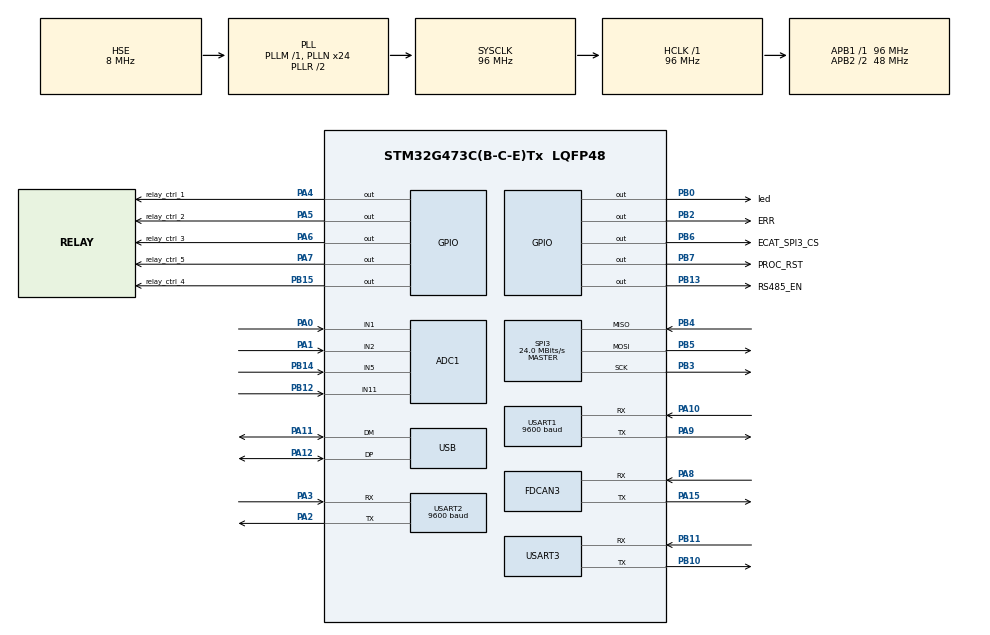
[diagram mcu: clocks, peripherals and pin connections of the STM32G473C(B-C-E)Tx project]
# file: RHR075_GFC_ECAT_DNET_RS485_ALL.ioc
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ADC1.Channel-0\#ChannelRegularConversion=ADC_CHANNEL_1
ADC1.Channel-1\#ChannelRegularConversion=ADC_CHANNEL_2
ADC1.Channel-2\#ChannelRegularConversion=ADC_CHANNEL_5
ADC1.Channel-3\#ChannelRegularConversion=ADC_CHANNEL_11
ADC1.Channel-4\#ChannelRegularConversion=ADC_CHANNEL_VREFINT
ADC1.ClockPrescaler=ADC_CLOCK_SYNC_PCLK_DIV2
ADC1.ContinuousConvMode=ENABLE
ADC1.DMAContinuousRequests=DISABLE
ADC1.NbrOfConversion=5
ADC1.NbrOfConversionFlag=1
ADC1.OffsetNumber-0\#ChannelRegularConversion=ADC_OFFSET_NONE
ADC1.OffsetNumber-1\#ChannelRegularConversion=ADC_OFFSET_NONE
ADC1.OffsetNumber-2\#ChannelRegularConversion=ADC_OFFSET_NONE
ADC1.OffsetNumber-3\#ChannelRegularConversion=ADC_OFFSET_NONE
ADC1.OffsetNumber-4\#ChannelRegularConversion=ADC_OFFSET_NONE
ADC1.Rank-0\#ChannelRegularConversion=1
ADC1.Rank-1\#ChannelRegularConversion=2
ADC1.Rank-2\#ChannelRegularConversion=3
ADC1.Rank-3\#ChannelRegularConversion=4
ADC1.Rank-4\#ChannelRegularConversion=5
ADC1.SamplingTime-0\#ChannelRegularConversion=ADC_SAMPLETIME_92CYCLES_5
ADC1.SamplingTime-1\#ChannelRegularConversion=ADC_SAMPLETIME_92CYCLES_5
ADC1.SamplingTime-2\#ChannelRegularConversion=ADC_SAMPLETIME_92CYCLES_5
ADC1.SamplingTime-3\#ChannelRegularConversion=ADC_SAMPLETIME_92CYCLES_5
ADC1.SamplingTime-4\#ChannelRegularConversion=ADC_SAMPLETIME_92CYCLES_5
ADC1.master=1
Dma.ADC1.0.Direction=DMA_PERIPH_TO_MEMORY
Dma.ADC1.0.EventEnable=DISABLE
Dma.ADC1.0.Instance=DMA1_Channel1
Dma.ADC1.0.MemDataAlignment=DMA_MDATAALIGN_HALFWORD
Dma.ADC1.0.MemInc=DMA_MINC_ENABLE
Dma.ADC1.0.Mode=DMA_CIRCULAR
Dma.ADC1.0.PeriphDataAlignment=DMA_PDATAALIGN_HALFWORD
Dma.ADC1.0.PeriphInc=DMA_PINC_DISABLE
Dma.ADC1.0.Polarity=HAL_DMAMUX_REQ_GEN_RISING
Dma.ADC1.0.Priority=DMA_PRIORITY_LOW
Dma.ADC1.0.RequestNumber=1
Dma.ADC1.0.SignalID=NONE
Dma.ADC1.0.SyncEnable=DISABLE
Dma.ADC1.0.SyncPolarity=HAL_DMAMUX_SYNC_NO_EVENT
Dma.ADC1.0.SyncRequestNumber=1
Dma.ADC1.0.SyncSignalID=NONE
Dma.Request0=ADC1
Dma.Request1=USART2_RX
Dma.Request2=USART3_RX
Dma.USART2_RX.1.Direction=DMA_PERIPH_TO_MEMORY
Dma.USART2_RX.1.EventEnable=DISABLE
Dma.USART2_RX.1.Instance=DMA1_Channel3
Dma.USART2_RX.1.MemDataAlignment=DMA_MDATAALIGN_BYTE
Dma.USART2_RX.1.MemInc=DMA_MINC_ENABLE
Dma.USART2_RX.1.Mode=DMA_NORMAL
Dma.USART2_RX.1.PeriphDataAlignment=DMA_PDATAALIGN_BYTE
Dma.USART2_RX.1.PeriphInc=DMA_PINC_DISABLE
Dma.USART2_RX.1.Polarity=HAL_DMAMUX_REQ_GEN_RISING
Dma.USART2_RX.1.Priority=DMA_PRIORITY_LOW
Dma.USART2_RX.1.RequestNumber=1
Dma.USART2_RX.1.SignalID=NONE
Dma.USART2_RX.1.SyncEnable=DISABLE
Dma.USART2_RX.1.SyncPolarity=HAL_DMAMUX_SYNC_NO_EVENT
Dma.USART2_RX.1.SyncRequestNumber=1
Dma.USART2_RX.1.SyncSignalID=NONE
Dma.USART3_RX.2.Direction=DMA_PERIPH_TO_MEMORY
Dma.USART3_RX.2.EventEnable=DISABLE
Dma.USART3_RX.2.Instance=DMA1_Channel4
Dma.USART3_RX.2.MemDataAlignment=DMA_MDATAALIGN_BYTE
Dma.USART3_RX.2.MemInc=DMA_MINC_ENABLE
Dma.USART3_RX.2.Mode=DMA_NORMAL
Dma.USART3_RX.2.PeriphDataAlignment=DMA_PDATAALIGN_BYTE
Dma.USART3_RX.2.PeriphInc=DMA_PINC_DISABLE
Dma.USART3_RX.2.Polarity=HAL_DMAMUX_REQ_GEN_RISING
Dma.USART3_RX.2.Priority=DMA_PRIORITY_LOW
Dma.USART3_RX.2.RequestNumber=1
Dma.USART3_RX.2.SignalID=NONE
Dma.USART3_RX.2.SyncEnable=DISABLE
Dma.USART3_RX.2.SyncPolarity=HAL_DMAMUX_SYNC_NO_EVENT
Dma.USART3_RX.2.SyncRequestNumber=1
Dma.USART3_RX.2.SyncSignalID=NONE
FDCAN3.CalculateBaudRateNominal=1200000
FDCAN3.CalculateTimeBitNominal=833
FDCAN3.CalculateTimeQuantumNominal=166.66666666666666
Mcu.Family=STM32G4
Mcu.Name=STM32G473C(B-C-E)Tx
Mcu.Package=LQFP48
NVIC.ADC1_2_IRQn=true\:0\:0\:false\:false\:true\:true\:true\:true
NVIC.DMA1_Channel1_IRQn=true\:0\:0\:false\:false\:true\:false\:true\:true
NVIC.DMA1_Channel3_IRQn=true\:0\:0\:false\:false\:true\:false\:true\:true
NVIC.DMA1_Channel4_IRQn=true\:0\:0\:false\:false\:true\:false\:true\:true
NVIC.PriorityGroup=NVIC_PRIORITYGROUP_4
NVIC.USART1_IRQn=true\:0\:0\:false\:false\:true\:true\:true\:true
NVIC.USART2_IRQn=true\:0\:0\:false\:false\:true\:true\:true\:true
NVIC.USART3_IRQn=true\:0\:0\:false\:false\:true\:true\:true\:true
PA0.Mode=IN1-Single-Ended
PA0.Signal=ADC1_IN1
PA1.Mode=IN2-Single-Ended
PA1.Signal=ADC1_IN2
PA10.Mode=Asynchronous
PA10.Signal=USART1_RX
PA11.Mode=Device
PA11.Signal=USB_DM
PA12.Mode=Device
PA12.Signal=USB_DP
PA13.Mode=Serial_Wire
PA13.Signal=SYS_JTMS-SWDIO
PA14.Mode=Serial_Wire
PA14.Signal=SYS_JTCK-SWCLK
PA15.Mode=FDCAN_Activate
PA15.Signal=FDCAN3_TX
PA2.Mode=Asynchronous
PA2.Signal=USART2_TX
PA3.Mode=Asynchronous
PA3.Signal=USART2_RX
PA4.GPIO_Label=relay_ctrl_1
PA4.GPIO_PuPd=GPIO_PULLUP
PA4.PinState=GPIO_PIN_SET
PA4.Signal=GPIO_Output
PA5.GPIO_Label=relay_ctrl_2
PA5.GPIO_PuPd=GPIO_PULLUP
PA5.PinState=GPIO_PIN_SET
PA5.Signal=GPIO_Output
PA6.GPIO_Label=relay_ctrl_3
PA6.GPIO_PuPd=GPIO_PULLUP
PA6.PinState=GPIO_PIN_SET
PA6.Signal=GPIO_Output
PA7.GPIO_Label=relay_ctrl_5
PA7.GPIO_PuPd=GPIO_PULLUP
PA7.PinState=GPIO_PIN_SET
PA7.Signal=GPIO_Output
PA8.Mode=FDCAN_Activate
PA8.Signal=FDCAN3_RX
PA9.Mode=Asynchronous
PA9.Signal=USART1_TX
PB0.GPIO_Label=led
PB0.Signal=GPIO_Output
PB10.Mode=Asynchronous
PB10.Signal=USART3_TX
PB11.Mode=Asynchronous
PB11.Signal=USART3_RX
PB12.Mode=IN11-Single-Ended
PB12.Signal=ADC1_IN11
PB13.GPIO_Label=RS485_EN
PB13.GPIO_PuPd=GPIO_PULLDOWN
PB13.Signal=GPIO_Output
PB14.Mode=IN5-Single-Ended
PB14.Signal=ADC1_IN5
PB15.GPIO_Label=relay_ctrl_4
PB15.GPIO_PuPd=GPIO_PULLUP
PB15.PinState=GPIO_PIN_SET
PB15.Signal=GPIO_Output
PB2.GPIO_Label=ERR
PB2.Signal=GPIO_Output
PB3.Mode=Full_Duplex_Master
PB3.Signal=SPI3_SCK
PB4.Mode=Full_Duplex_Master
PB4.Signal=SPI3_MISO
PB5.Mode=Full_Duplex_Master
PB5.Signal=SPI3_MOSI
PB6.GPIO_Label=ECAT_SPI3_CS
PB6.GPIO_PuPd=GPIO_PULLUP
PB6.PinState=GPIO_PIN_SET
PB6.Signal=GPIO_Output
PB7.GPIO_Label=PROC_RST
PB7.GPIO_PuPd=GPIO_PULLUP
PB7.PinState=GPIO_PIN_SET
PB7.Signal=GPIO_Output
PF0-OSC_IN.Mode=HSE-External-Oscillator
PF0-OSC_IN.Signal=RCC_OSC_IN
PF1-OSC_OUT.Mode=HSE-External-Oscillator
PF1-OSC_OUT.Signal=RCC_OSC_OUT
ProjectManager.HeapSize=0x200
ProjectManager.StackSize=0x400
ProjectManager.TargetToolchain=MDK-ARM V5.32
RCC.ADC12Freq_Value=96000000
RCC.ADC345Freq_Value=96000000
RCC.AHBFreq_Value=96000000
RCC.APB1Freq_Value=96000000
RCC.APB1TimFreq_Value=96000000
RCC.APB2CLKDivider=RCC_HCLK_DIV2
RCC.APB2Freq_Value=48000000
RCC.APB2TimFreq_Value=96000000
RCC.CortexFreq_Value=96000000
RCC.EXTERNAL_CLOCK_VALUE=12288000
RCC.HCLKFreq_Value=96000000
RCC.HSE_VALUE=8000000
RCC.HSI48_VALUE=48000000
RCC.HSI_VALUE=16000000
RCC.LSE_VALUE=32768
RCC.PLLN=24
RCC.PLLQ=RCC_PLLQ_DIV4
RCC.PLLSourceVirtual=RCC_PLLSOURCE_HSE
RCC.SYSCLKFreq_VALUE=96000000
RCC.SYSCLKSource=RCC_SYSCLKSOURCE_PLLCLK
RCC.USBFreq_Value=48000000
RCC.VCOOutputFreq_Value=192000000
SPI3.BaudRatePrescaler=SPI_BAUDRATEPRESCALER_4
SPI3.CalculateBaudRate=24.0 MBits/s
SPI3.Direction=SPI_DIRECTION_2LINES
SPI3.Mode=SPI_MODE_MASTER
SPI3.VirtualType=VM_MASTER
USART1.BaudRate=9600
USART1.VirtualMode-Asynchronous=VM_ASYNC
USART2.BaudRate=9600
USART2.VirtualMode-Asynchronous=VM_ASYNC
USART3.VirtualMode-Asynchronous=VM_ASYNC
VP_ADC1_Vref_Input.Mode=IN-Vrefint
VP_SYS_VS_DBSignals.Mode=DisableDeadBatterySignals
board=custom

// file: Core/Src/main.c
/* USER CODE BEGIN Header */
/**
  ******************************************************************************
  * @file           : main.c
  * @brief          : Main program body
  ******************************************************************************
  * @attention
  *
  * Copyright (c) 2024 STMicroelectronics.
  * All rights reserved.
  *
  * This software is licensed under terms that can be found in the LICENSE file
  * in the root directory of this software component.
  * If no LICENSE file comes with this software, it is provided AS-IS.
  *
  ******************************************************************************
  */
/* USER CODE END Header */
#include "main.h"

/* USER CODE BEGIN Includes */
#include "app.h"
/* USER CODE END Includes */

ADC_HandleTypeDef hadc1;
DMA_HandleTypeDef hdma_adc1;

FDCAN_HandleTypeDef hfdcan3;

SPI_HandleTypeDef hspi3;

UART_HandleTypeDef huart1;
UART_HandleTypeDef huart2;
UART_HandleTypeDef huart3;
DMA_HandleTypeDef hdma_usart2_rx;
DMA_HandleTypeDef hdma_usart3_rx;

PCD_HandleTypeDef hpcd_USB_FS;

void SystemClock_Config(void);
static void MX_GPIO_Init(void);
static void MX_DMA_Init(void);
static void MX_ADC1_Init(void);
static void MX_FDCAN3_Init(void);
static void MX_SPI3_Init(void);
static void MX_USART1_UART_Init(void);
static void MX_USART2_UART_Init(void);
static void MX_USART3_UART_Init(void);
static void MX_USB_PCD_Init(void);

int main(void)
{

  /* MCU Configuration--------------------------------------------------------*/

  /* Reset of all peripherals, Initializes the Flash interface and the Systick. */
  HAL_Init();

  /* Configure the system clock */
  SystemClock_Config();

  /* Initialize all configured peripherals */
  MX_GPIO_Init();
  MX_DMA_Init();
  MX_ADC1_Init();
  MX_FDCAN3_Init();
  MX_SPI3_Init();
  MX_USART1_UART_Init();
  MX_USART2_UART_Init();
  MX_USART3_UART_Init();
  MX_USB_PCD_Init();
  /* USER CODE BEGIN 2 */
   app_init();
  #if DEBUG_LOG2_ENABLE
	 printf("init ok\r\n");
  #endif
  /* USER CODE END 2 */

  /* Infinite loop */
  /* USER CODE BEGIN WHILE */
  while (1)
  {
		  app_proc();

    /* USER CODE END WHILE */

  }
}

void SystemClock_Config(void)
{
  RCC_OscInitTypeDef RCC_OscInitStruct = {0};
  RCC_ClkInitTypeDef RCC_ClkInitStruct = {0};

  /** Configure the main internal regulator output voltage
  */
  HAL_PWREx_ControlVoltageScaling(PWR_REGULATOR_VOLTAGE_SCALE1);

  /** Initializes the RCC Oscillators according to the specified parameters
  * in the RCC_OscInitTypeDef structure.
  */
  RCC_OscInitStruct.OscillatorType = RCC_OSCILLATORTYPE_HSE;
  RCC_OscInitStruct.HSEState = RCC_HSE_ON;
  RCC_OscInitStruct.PLL.PLLState = RCC_PLL_ON;
  RCC_OscInitStruct.PLL.PLLSource = RCC_PLLSOURCE_HSE;
  RCC_OscInitStruct.PLL.PLLM = RCC_PLLM_DIV1;
  RCC_OscInitStruct.PLL.PLLN = 24;
  RCC_OscInitStruct.PLL.PLLP = RCC_PLLP_DIV2;
  RCC_OscInitStruct.PLL.PLLQ = RCC_PLLQ_DIV4;
  RCC_OscInitStruct.PLL.PLLR = RCC_PLLR_DIV2;
  if (HAL_RCC_OscConfig(&RCC_OscInitStruct) != HAL_OK)
  {
    Error_Handler();
  }

  /** Initializes the CPU, AHB and APB buses clocks
  */
  RCC_ClkInitStruct.ClockType = RCC_CLOCKTYPE_HCLK|RCC_CLOCKTYPE_SYSCLK
                              |RCC_CLOCKTYPE_PCLK1|RCC_CLOCKTYPE_PCLK2;
  RCC_ClkInitStruct.SYSCLKSource = RCC_SYSCLKSOURCE_PLLCLK;
  RCC_ClkInitStruct.AHBCLKDivider = RCC_SYSCLK_DIV1;
  RCC_ClkInitStruct.APB1CLKDivider = RCC_HCLK_DIV1;
  RCC_ClkInitStruct.APB2CLKDivider = RCC_HCLK_DIV2;

  if (HAL_RCC_ClockConfig(&RCC_ClkInitStruct, FLASH_LATENCY_3) != HAL_OK)
  {
    Error_Handler();
  }
}

static void MX_ADC1_Init(void)
{

  ADC_MultiModeTypeDef multimode = {0};
  ADC_ChannelConfTypeDef sConfig = {0};

  /** Common config
  */
  hadc1.Instance = ADC1;
  hadc1.Init.ClockPrescaler = ADC_CLOCK_SYNC_PCLK_DIV2;
  hadc1.Init.Resolution = ADC_RESOLUTION_12B;
  hadc1.Init.DataAlign = ADC_DATAALIGN_RIGHT;
  hadc1.Init.GainCompensation = 0;
  hadc1.Init.ScanConvMode = ADC_SCAN_ENABLE;
  hadc1.Init.EOCSelection = ADC_EOC_SINGLE_CONV;
  hadc1.Init.LowPowerAutoWait = DISABLE;
  hadc1.Init.ContinuousConvMode = ENABLE;
  hadc1.Init.NbrOfConversion = 5;
  hadc1.Init.DiscontinuousConvMode = DISABLE;
  hadc1.Init.ExternalTrigConv = ADC_SOFTWARE_START;
  hadc1.Init.ExternalTrigConvEdge = ADC_EXTERNALTRIGCONVEDGE_NONE;
  hadc1.Init.DMAContinuousRequests = DISABLE;
  hadc1.Init.Overrun = ADC_OVR_DATA_PRESERVED;
  hadc1.Init.OversamplingMode = DISABLE;
  if (HAL_ADC_Init(&hadc1) != HAL_OK)
  {
    Error_Handler();
  }

  /** Configure the ADC multi-mode
  */
  multimode.Mode = ADC_MODE_INDEPENDENT;
  if (HAL_ADCEx_MultiModeConfigChannel(&hadc1, &multimode) != HAL_OK)
  {
    Error_Handler();
  }

  /** Configure Regular Channel
  */
  sConfig.Channel = ADC_CHANNEL_1;
  sConfig.Rank = ADC_REGULAR_RANK_1;
  sConfig.SamplingTime = ADC_SAMPLETIME_24CYCLES_5;
  sConfig.SingleDiff = ADC_SINGLE_ENDED;
  sConfig.OffsetNumber = ADC_OFFSET_NONE;
  sConfig.Offset = 0;
  if (HAL_ADC_ConfigChannel(&hadc1, &sConfig) != HAL_OK)
  {
    Error_Handler();
  }

  /** Configure Regular Channel
  */
  sConfig.Channel = ADC_CHANNEL_2;
  sConfig.Rank = ADC_REGULAR_RANK_2;
  if (HAL_ADC_ConfigChannel(&hadc1, &sConfig) != HAL_OK)
  {
    Error_Handler();
  }

  /** Configure Regular Channel
  */
  sConfig.Channel = ADC_CHANNEL_5;
  sConfig.Rank = ADC_REGULAR_RANK_3;
  if (HAL_ADC_ConfigChannel(&hadc1, &sConfig) != HAL_OK)
  {
    Error_Handler();
  }

  /** Configure Regular Channel
  */
  sConfig.Channel = ADC_CHANNEL_11;
  sConfig.Rank = ADC_REGULAR_RANK_4;
  if (HAL_ADC_ConfigChannel(&hadc1, &sConfig) != HAL_OK)
  {
    Error_Handler();
  }

  /** Configure Regular Channel
  */
  sConfig.Channel = ADC_CHANNEL_VREFINT;
  sConfig.Rank = ADC_REGULAR_RANK_5;
  if (HAL_ADC_ConfigChannel(&hadc1, &sConfig) != HAL_OK)
  {
    Error_Handler();
  }

}

static void MX_FDCAN3_Init(void)
{

  hfdcan3.Instance = FDCAN3;
  hfdcan3.Init.ClockDivider = FDCAN_CLOCK_DIV1;
  hfdcan3.Init.FrameFormat = FDCAN_FRAME_CLASSIC;
  hfdcan3.Init.Mode = FDCAN_MODE_NORMAL;
  hfdcan3.Init.AutoRetransmission = DISABLE;
  hfdcan3.Init.TransmitPause = DISABLE;
  hfdcan3.Init.ProtocolException = DISABLE;
  hfdcan3.Init.NominalPrescaler = 16;
  hfdcan3.Init.NominalSyncJumpWidth = 1;
  hfdcan3.Init.NominalTimeSeg1 = 2;
  hfdcan3.Init.NominalTimeSeg2 = 2;
  hfdcan3.Init.DataPrescaler = 1;
  hfdcan3.Init.DataSyncJumpWidth = 1;
  hfdcan3.Init.DataTimeSeg1 = 1;
  hfdcan3.Init.DataTimeSeg2 = 1;
  hfdcan3.Init.StdFiltersNbr = 0;
  hfdcan3.Init.ExtFiltersNbr = 0;
  hfdcan3.Init.TxFifoQueueMode = FDCAN_TX_FIFO_OPERATION;
  if (HAL_FDCAN_Init(&hfdcan3) != HAL_OK)
  {
    Error_Handler();
  }

}

static void MX_SPI3_Init(void)
{

  /* SPI3 parameter configuration*/
  hspi3.Instance = SPI3;
  hspi3.Init.Mode = SPI_MODE_MASTER;
  hspi3.Init.Direction = SPI_DIRECTION_2LINES;
  hspi3.Init.DataSize = SPI_DATASIZE_4BIT;
  hspi3.Init.CLKPolarity = SPI_POLARITY_LOW;
  hspi3.Init.CLKPhase = SPI_PHASE_1EDGE;
  hspi3.Init.NSS = SPI_NSS_SOFT;
  hspi3.Init.BaudRatePrescaler = SPI_BAUDRATEPRESCALER_4;
  hspi3.Init.FirstBit = SPI_FIRSTBIT_MSB;
  hspi3.Init.TIMode = SPI_TIMODE_DISABLE;
  hspi3.Init.CRCCalculation = SPI_CRCCALCULATION_DISABLE;
  hspi3.Init.CRCPolynomial = 7;
  hspi3.Init.CRCLength = SPI_CRC_LENGTH_DATASIZE;
  hspi3.Init.NSSPMode = SPI_NSS_PULSE_ENABLE;
  if (HAL_SPI_Init(&hspi3) != HAL_OK)
  {
    Error_Handler();
  }

}

static void MX_USART1_UART_Init(void)
{

  huart1.Instance = USART1;
  huart1.Init.BaudRate = 9600;
  huart1.Init.WordLength = UART_WORDLENGTH_8B;
  huart1.Init.StopBits = UART_STOPBITS_1;
  huart1.Init.Parity = UART_PARITY_NONE;
  huart1.Init.Mode = UART_MODE_TX_RX;
  huart1.Init.HwFlowCtl = UART_HWCONTROL_NONE;
  huart1.Init.OverSampling = UART_OVERSAMPLING_16;
  huart1.Init.OneBitSampling = UART_ONE_BIT_SAMPLE_DISABLE;
  huart1.Init.ClockPrescaler = UART_PRESCALER_DIV1;
  huart1.AdvancedInit.AdvFeatureInit = UART_ADVFEATURE_NO_INIT;
  if (HAL_UART_Init(&huart1) != HAL_OK)
  {
    Error_Handler();
  }
  if (HAL_UARTEx_SetTxFifoThreshold(&huart1, UART_TXFIFO_THRESHOLD_1_8) != HAL_OK)
  {
    Error_Handler();
  }
  if (HAL_UARTEx_SetRxFifoThreshold(&huart1, UART_RXFIFO_THRESHOLD_1_8) != HAL_OK)
  {
    Error_Handler();
  }
  if (HAL_UARTEx_DisableFifoMode(&huart1) != HAL_OK)
  {
    Error_Handler();
  }

}

static void MX_USART2_UART_Init(void)
{

  huart2.Instance = USART2;
  huart2.Init.BaudRate = 9600;
  huart2.Init.WordLength = UART_WORDLENGTH_8B;
  huart2.Init.StopBits = UART_STOPBITS_1;
  huart2.Init.Parity = UART_PARITY_NONE;
  huart2.Init.Mode = UART_MODE_TX_RX;
  huart2.Init.HwFlowCtl = UART_HWCONTROL_NONE;
  huart2.Init.OverSampling = UART_OVERSAMPLING_16;
  huart2.Init.OneBitSampling = UART_ONE_BIT_SAMPLE_DISABLE;
  huart2.Init.ClockPrescaler = UART_PRESCALER_DIV1;
  huart2.AdvancedInit.AdvFeatureInit = UART_ADVFEATURE_NO_INIT;
  if (HAL_UART_Init(&huart2) != HAL_OK)
  {
    Error_Handler();
  }
  if (HAL_UARTEx_SetTxFifoThreshold(&huart2, UART_TXFIFO_THRESHOLD_1_8) != HAL_OK)
  {
    Error_Handler();
  }
  if (HAL_UARTEx_SetRxFifoThreshold(&huart2, UART_RXFIFO_THRESHOLD_1_8) != HAL_OK)
  {
    Error_Handler();
  }
  if (HAL_UARTEx_DisableFifoMode(&huart2) != HAL_OK)
  {
    Error_Handler();
  }

}

static void MX_USART3_UART_Init(void)
{

  huart3.Instance = USART3;
  huart3.Init.BaudRate = 115200;
  huart3.Init.WordLength = UART_WORDLENGTH_8B;
  huart3.Init.StopBits = UART_STOPBITS_1;
  huart3.Init.Parity = UART_PARITY_NONE;
  huart3.Init.Mode = UART_MODE_TX_RX;
  huart3.Init.HwFlowCtl = UART_HWCONTROL_NONE;
  huart3.Init.OverSampling = UART_OVERSAMPLING_16;
  huart3.Init.OneBitSampling = UART_ONE_BIT_SAMPLE_DISABLE;
  huart3.Init.ClockPrescaler = UART_PRESCALER_DIV1;
  huart3.AdvancedInit.AdvFeatureInit = UART_ADVFEATURE_NO_INIT;
  if (HAL_UART_Init(&huart3) != HAL_OK)
  {
    Error_Handler();
  }
  if (HAL_UARTEx_SetTxFifoThreshold(&huart3, UART_TXFIFO_THRESHOLD_1_8) != HAL_OK)
  {
    Error_Handler();
  }
  if (HAL_UARTEx_SetRxFifoThreshold(&huart3, UART_RXFIFO_THRESHOLD_1_8) != HAL_OK)
  {
    Error_Handler();
  }
  if (HAL_UARTEx_DisableFifoMode(&huart3) != HAL_OK)
  {
    Error_Handler();
  }

}

static void MX_USB_PCD_Init(void)
{

  hpcd_USB_FS.Instance = USB;
  hpcd_USB_FS.Init.dev_endpoints = 8;
  hpcd_USB_FS.Init.speed = PCD_SPEED_FULL;
  hpcd_USB_FS.Init.phy_itface = PCD_PHY_EMBEDDED;
  hpcd_USB_FS.Init.Sof_enable = DISABLE;
  hpcd_USB_FS.Init.low_power_enable = DISABLE;
  hpcd_USB_FS.Init.lpm_enable = DISABLE;
  hpcd_USB_FS.Init.battery_charging_enable = DISABLE;
  if (HAL_PCD_Init(&hpcd_USB_FS) != HAL_OK)
  {
    Error_Handler();
  }

}

static void MX_DMA_Init(void)
{

  /* DMA controller clock enable */
  __HAL_RCC_DMAMUX1_CLK_ENABLE();
  __HAL_RCC_DMA1_CLK_ENABLE();

  /* DMA interrupt init */
  /* DMA1_Channel1_IRQn interrupt configuration */
  HAL_NVIC_SetPriority(DMA1_Channel1_IRQn, 0, 0);
  HAL_NVIC_EnableIRQ(DMA1_Channel1_IRQn);
  /* DMA1_Channel3_IRQn interrupt configuration */
  HAL_NVIC_SetPriority(DMA1_Channel3_IRQn, 0, 0);
  HAL_NVIC_EnableIRQ(DMA1_Channel3_IRQn);
  /* DMA1_Channel4_IRQn interrupt configuration */
  HAL_NVIC_SetPriority(DMA1_Channel4_IRQn, 0, 0);
  HAL_NVIC_EnableIRQ(DMA1_Channel4_IRQn);

}

static void MX_GPIO_Init(void)
{
  GPIO_InitTypeDef GPIO_InitStruct = {0};

  /* GPIO Ports Clock Enable */
  __HAL_RCC_GPIOF_CLK_ENABLE();
  __HAL_RCC_GPIOA_CLK_ENABLE();
  __HAL_RCC_GPIOB_CLK_ENABLE();

  /*Configure GPIO pin Output Level */
  HAL_GPIO_WritePin(GPIOA, relay_ctrl_1_Pin|relay_ctrl_2_Pin|relay_ctrl_3_Pin|relay_ctrl_5_Pin, GPIO_PIN_SET);

  /*Configure GPIO pin Output Level */
  HAL_GPIO_WritePin(GPIOB, led_Pin|ERR_Pin|RS485_EN_Pin, GPIO_PIN_RESET);

  /*Configure GPIO pin Output Level */
  HAL_GPIO_WritePin(GPIOB, relay_ctrl_4_Pin|ECAT_SPI3_CS_Pin|PROC_RST_Pin, GPIO_PIN_SET);

  /*Configure GPIO pins : relay_ctrl_1_Pin relay_ctrl_2_Pin relay_ctrl_3_Pin relay_ctrl_5_Pin */
  GPIO_InitStruct.Pin = relay_ctrl_1_Pin|relay_ctrl_2_Pin|relay_ctrl_3_Pin|relay_ctrl_5_Pin;
  GPIO_InitStruct.Mode = GPIO_MODE_OUTPUT_PP;
  GPIO_InitStruct.Pull = GPIO_PULLUP;
  GPIO_InitStruct.Speed = GPIO_SPEED_FREQ_LOW;
  HAL_GPIO_Init(GPIOA, &GPIO_InitStruct);

  /*Configure GPIO pins : led_Pin ERR_Pin */
  GPIO_InitStruct.Pin = led_Pin|ERR_Pin;
  GPIO_InitStruct.Mode = GPIO_MODE_OUTPUT_PP;
  GPIO_InitStruct.Pull = GPIO_NOPULL;
  GPIO_InitStruct.Speed = GPIO_SPEED_FREQ_LOW;
  HAL_GPIO_Init(GPIOB, &GPIO_InitStruct);

  /*Configure GPIO pin : RS485_EN_Pin */
  GPIO_InitStruct.Pin = RS485_EN_Pin;
  GPIO_InitStruct.Mode = GPIO_MODE_OUTPUT_PP;
  GPIO_InitStruct.Pull = GPIO_PULLDOWN;
  GPIO_InitStruct.Speed = GPIO_SPEED_FREQ_LOW;
  HAL_GPIO_Init(RS485_EN_GPIO_Port, &GPIO_InitStruct);

  /*Configure GPIO pins : relay_ctrl_4_Pin ECAT_SPI3_CS_Pin PROC_RST_Pin */
  GPIO_InitStruct.Pin = relay_ctrl_4_Pin|ECAT_SPI3_CS_Pin|PROC_RST_Pin;
  GPIO_InitStruct.Mode = GPIO_MODE_OUTPUT_PP;
  GPIO_InitStruct.Pull = GPIO_PULLUP;
  GPIO_InitStruct.Speed = GPIO_SPEED_FREQ_LOW;
  HAL_GPIO_Init(GPIOB, &GPIO_InitStruct);

}

void Error_Handler(void)
{
  __disable_irq();
  while (1)
  {
  }
}
